# ATSAM3N0C device description
Architecture: CORTEX-M3; Family: SAM3; Series: SAM3N
Registers are 32-bit, read-write, no defined reset value unless marked. A register's access mark holds for its fields unless they carry their own. Offsets are from the block's base; [hi:lo] are bit positions; {n}, {i} and the like mark numbered series.

## RSTC — Reset Controller
Instances: RSTC 0x400E1400
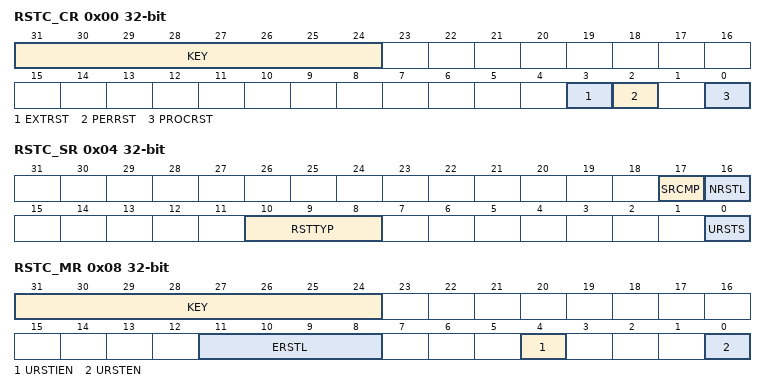
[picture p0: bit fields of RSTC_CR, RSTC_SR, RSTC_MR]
0x00 RSTC_CR wo — Control Register
  [31:24] KEY — Password
  [3] EXTRST — External Reset
  [2] PERRST — Peripheral Reset
  [0] PROCRST — Processor Reset
0x04 RSTC_SR ro — Status Register
  [17] SRCMP — Software Reset Command in Progress
  [16] NRSTL — NRST Pin Level
  [10:8] RSTTYP — Reset Type
  [0] URSTS — User Reset Status
0x08 RSTC_MR — Mode Register
  [31:24] KEY — Password
  [11:8] ERSTL — External Reset Length
  [4] URSTIEN — User Reset Interrupt Enable
  [0] URSTEN — User Reset Enable

## RTC — Real-time Clock
Instances: RTC 0x400E1460
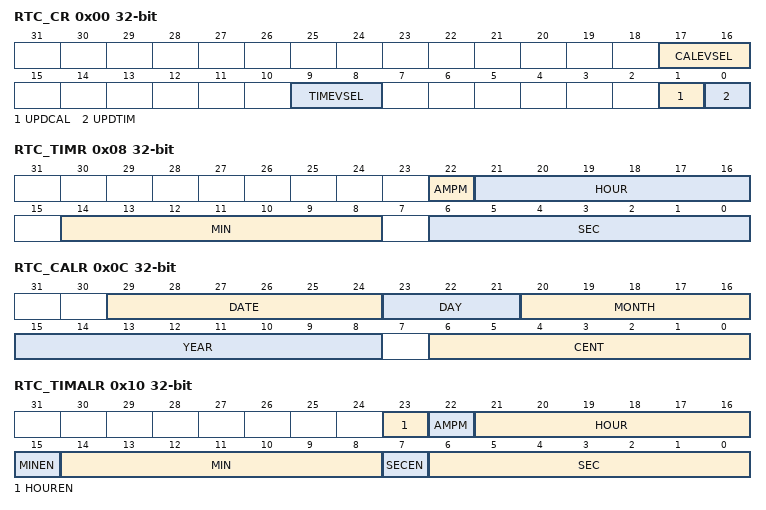
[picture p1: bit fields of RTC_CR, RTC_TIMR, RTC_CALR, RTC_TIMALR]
0x00 RTC_CR — Control Register
  [17:16] CALEVSEL — Calendar Event Selection
    0=WEEK (Week change (every Monday at time 00:00:00)); 1=MONTH (Month change (every 01 of each month at time 00:00:00)); 2=YEAR (Year change (every January 1 at time 00:00:00))
  [9:8] TIMEVSEL — Time Event Selection
    0=MINUTE (Minute change); 1=HOUR (Hour change); 2=MIDNIGHT (Every day at midnight); 3=NOON (Every day at noon)
  [1] UPDCAL — Update Request Calendar Register
  [0] UPDTIM — Update Request Time Register
0x04 RTC_MR — Mode Register
  [0] HRMOD — 12-/24-hour Mode
0x08 RTC_TIMR — Time Register
  [22] AMPM — Ante Meridiem Post Meridiem Indicator
  [21:16] HOUR — Current Hour
  [14:8] MIN — Current Minute
  [6:0] SEC — Current Second
0x0C RTC_CALR — Calendar Register
  [29:24] DATE — Current Day in Current Month
  [23:21] DAY — Current Day in Current Week
  [20:16] MONTH — Current Month
  [15:8] YEAR — Current Year
  [6:0] CENT — Current Century
0x10 RTC_TIMALR — Time Alarm Register
  [23] HOUREN — Hour Alarm Enable
  [22] AMPM — AM/PM Indicator
  [21:16] HOUR — Hour Alarm
  [15] MINEN — Minute Alarm Enable
  [14:8] MIN — Minute Alarm
  [7] SECEN — Second Alarm Enable
  [6:0] SEC — Second Alarm
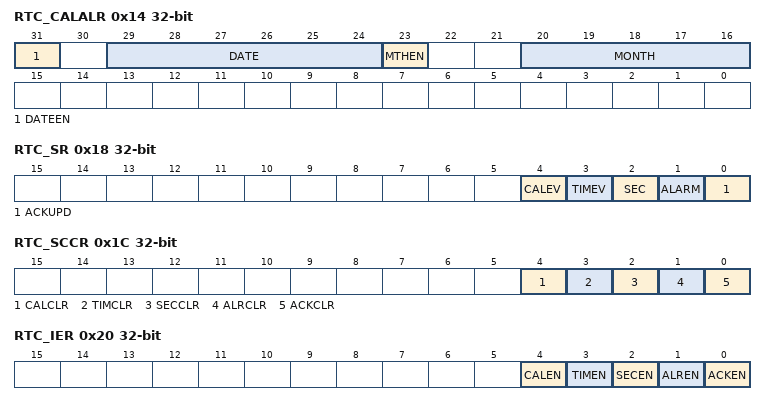
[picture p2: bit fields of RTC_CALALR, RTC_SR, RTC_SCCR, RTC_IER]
0x14 RTC_CALALR — Calendar Alarm Register
  [31] DATEEN — Date Alarm Enable
  [29:24] DATE — Date Alarm
  [23] MTHEN — Month Alarm Enable
  [20:16] MONTH — Month Alarm
0x18 RTC_SR ro — Status Register
  [4] CALEV — Calendar Event
  [3] TIMEV — Time Event
  [2] SEC — Second Event
  [1] ALARM — Alarm Flag
  [0] ACKUPD — Acknowledge for Update
0x1C RTC_SCCR wo — Status Clear Command Register
  [4] CALCLR — Calendar Clear
  [3] TIMCLR — Time Clear
  [2] SECCLR — Second Clear
  [1] ALRCLR — Alarm Clear
  [0] ACKCLR — Acknowledge Clear
0x20 RTC_IER wo — Interrupt Enable Register
  [4] CALEN — Calendar Event Interrupt Enable
  [3] TIMEN — Time Event Interrupt Enable
  [2] SECEN — Second Event Interrupt Enable
  [1] ALREN — Alarm Interrupt Enable
  [0] ACKEN — Acknowledge Update Interrupt Enable
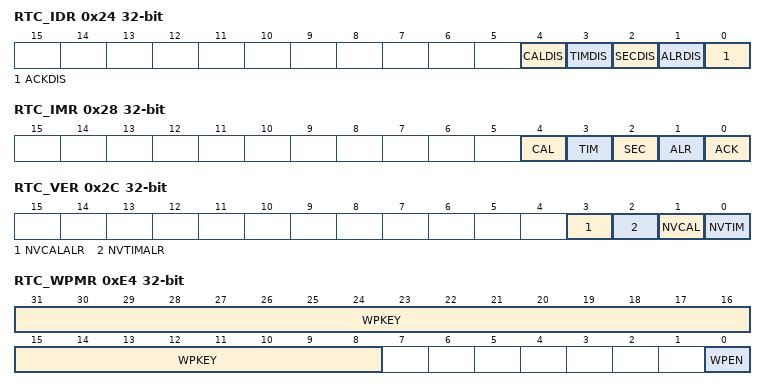
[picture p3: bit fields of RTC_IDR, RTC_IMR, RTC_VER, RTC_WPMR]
0x24 RTC_IDR wo — Interrupt Disable Register
  [4] CALDIS — Calendar Event Interrupt Disable
  [3] TIMDIS — Time Event Interrupt Disable
  [2] SECDIS — Second Event Interrupt Disable
  [1] ALRDIS — Alarm Interrupt Disable
  [0] ACKDIS — Acknowledge Update Interrupt Disable
0x28 RTC_IMR ro — Interrupt Mask Register
  [4] CAL — Calendar Event Interrupt Mask
  [3] TIM — Time Event Interrupt Mask
  [2] SEC — Second Event Interrupt Mask
  [1] ALR — Alarm Interrupt Mask
  [0] ACK — Acknowledge Update Interrupt Mask
0x2C RTC_VER ro — Valid Entry Register
  [3] NVCALALR — Non-valid Calendar Alarm
  [2] NVTIMALR — Non-valid Time Alarm
  [1] NVCAL — Non-valid Calendar
  [0] NVTIM — Non-valid Time
0xE4 RTC_WPMR — Write Protect Mode Register
  [31:8] WPKEY
  [0] WPEN — Write Protect Enable

## RTT — Real-time Timer
Instances: RTT 0x400E1430
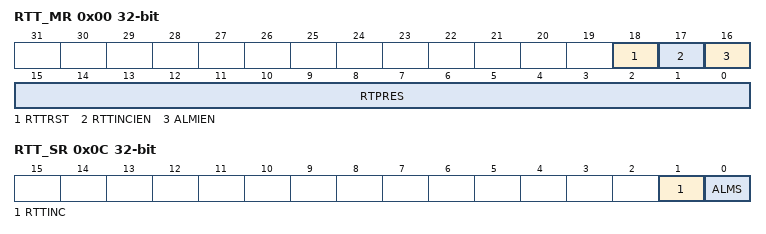
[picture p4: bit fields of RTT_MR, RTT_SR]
0x00 RTT_MR — Mode Register
  [18] RTTRST — Real-time Timer Restart
  [17] RTTINCIEN — Real-time Timer Increment Interrupt Enable
  [16] ALMIEN — Alarm Interrupt Enable
  [15:0] RTPRES — Real-time Timer Prescaler Value
0x04 RTT_AR — Alarm Register
  [31:0] ALMV — Alarm Value
0x08 RTT_VR ro — Value Register
  [31:0] CRTV — Current Real-time Value
0x0C RTT_SR ro — Status Register
  [1] RTTINC — Real-time Timer Increment
  [0] ALMS — Real-time Alarm Status

## WDT — Watchdog Timer
Instances: WDT 0x400E1450
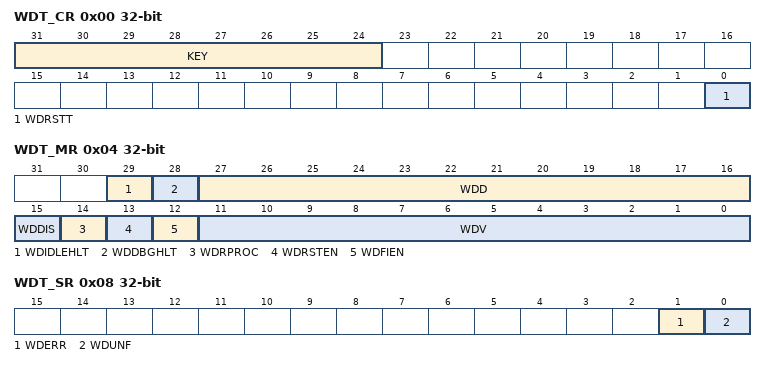
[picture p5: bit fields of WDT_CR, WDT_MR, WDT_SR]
0x00 WDT_CR wo — Control Register
  [31:24] KEY — Password
  [0] WDRSTT — Watchdog Restart
0x04 WDT_MR — Mode Register
  [29] WDIDLEHLT — Watchdog Idle Halt
  [28] WDDBGHLT — Watchdog Debug Halt
  [27:16] WDD — Watchdog Delta Value
  [15] WDDIS — Watchdog Disable
  [14] WDRPROC — Watchdog Reset Processor
  [13] WDRSTEN — Watchdog Reset Enable
  [12] WDFIEN — Watchdog Fault Interrupt Enable
  [11:0] WDV — Watchdog Counter Value
0x08 WDT_SR ro — Status Register
  [1] WDERR — Watchdog Error
  [0] WDUNF — Watchdog Underflow

## GPNVMBITS (FUSES module)
Instances: GPNVMBITS 0 in fuses
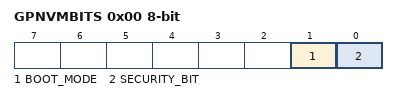
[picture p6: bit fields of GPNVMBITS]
0x00 GPNVMBITS 8-bit
  [1] BOOT_MODE — Boot Mode Selection
  [0] SECURITY_BIT ro

## LOCKBIT
Instances: LOCKBIT 0 in lockbits
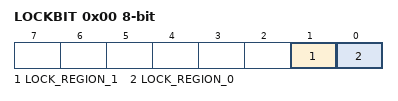
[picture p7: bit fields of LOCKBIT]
0x00 LOCKBIT 8-bit — Lock Bits
  [1] LOCK_REGION_1, [0] LOCK_REGION_0

## SysTick — System timer
Instances: SysTick 0xE000E010
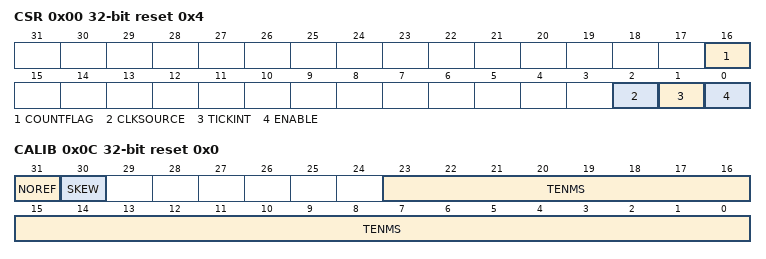
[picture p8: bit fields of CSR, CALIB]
0x00 CSR access not given reset 0x4 — SysTick Control and Status Register
  [16] COUNTFLAG
  [2] CLKSOURCE
    0=external clock; 1=processor clock
  [1] TICKINT
    0=counting down to 0 does not assert the SysTick exception request; 1=counting down to 0 asserts the SysTick exception request
  [0] ENABLE
    0=counter disabled; 1=counter enabled
0x04 RVR access not given reset 0x0 — SysTick Reload Value Register
  [23:0] RELOAD — Value to load into the SysTick Current Value Register when the counter reaches 0
0x08 CVR access not given reset 0x0 — SysTick Current Value Register
  [23:0] CURRENT — Current value at the time the register is accessed
0x0C CALIB access not given reset 0x0 — SysTick Calibration Value Register
  [31] NOREF
    0=The reference clock is provided; 1=The reference clock is not provided
  [30] SKEW
    0=10ms calibration value is exact; 1=10ms calibration value is inexact, because of the clock frequency
  [23:0] TENMS — Reload value to use for 10ms timing

## NVIC — Nested Vectored Interrupt Controller
Instances: NVIC 0xE000E100
{0x0+4i} NVICISER{i} access not given reset 0x0 (i=0..3) — Interrupt Set Enable Register n
  [31:0] SETENA — Interrupt set enable bits
{0x80+4i} NVICICER{i} access not given reset 0x0 (i=0..3) — Interrupt Clear Enable Register n
  [31:0] CLRENA — Interrupt clear-enable bits
{0x100+4i} NVICISPR{i} access not given reset 0x0 (i=0..3) — Interrupt Set Pending Register n
  [31:0] SETPEND — Interrupt set-pending bits
{0x180+4i} NVICICPR{i} access not given reset 0x0 (i=0..3) — Interrupt Clear Pending Register n
  [31:0] CLRPEND — Interrupt clear-pending bits
{0x200+4i} NVICIABR{i} access not given reset 0x0 (i=0..3) — Interrupt Active bit Register n
  [31:0] ACTIVE — Interrupt active flags
{0x300+i} NVICIP{i} 8-bit access not given reset 0x0 (i=0..105) — Interrupt Priority Register n
  [7:0] PRI{i} — Priority of interrupt {i}
0xE00 NVICSTIR access not given reset 0x0 — Software Trigger Interrupt Register
  [8:0] INTID — Interrupt ID of the interrupt to trigger, in the range 0-239. For example, a value of 0x03 specifies interrupt IRQ3.

## Notices in the file
SAM Software Package License
Copyright (c) %copyright_year%, Atmel Corporation
All rights reserved.
Redistribution and use in source and binary forms, with or without
modification, are permitted provided that the following condition is met:
- Redistributions of source code must retain the above copyright notice,
this list of conditions and the disclaimer below.
Atmel's name may not be used to endorse or promote products derived from
this software without specific prior written permission.
DISCLAIMER:  THIS SOFTWARE IS PROVIDED BY ATMEL "AS IS" AND ANY EXPRESS OR
IMPLIED WARRANTIES, INCLUDING, BUT NOT LIMITED TO, THE IMPLIED WARRANTIES OF
MERCHANTABILITY, FITNESS FOR A PARTICULAR PURPOSE AND NON-INFRINGEMENT ARE
DISCLAIMED. IN NO EVENT SHALL ATMEL BE LIABLE FOR ANY DIRECT, INDIRECT,
INCIDENTAL, SPECIAL, EXEMPLARY, OR CONSEQUENTIAL DAMAGES (INCLUDING, BUT NOT
LIMITED TO, PROCUREMENT OF SUBSTITUTE GOODS OR SERVICES; LOSS OF USE, DATA,
OR PROFITS; OR BUSINESS INTERRUPTION) HOWEVER CAUSED AND ON ANY THEORY OF
LIABILITY, WHETHER IN CONTRACT, STRICT LIABILITY, OR TORT (INCLUDING
NEGLIGENCE OR OTHERWISE) ARISING IN ANY WAY OUT OF THE USE OF THIS SOFTWARE,
EVEN IF ADVISED OF THE POSSIBILITY OF SUCH DAMAGE.
